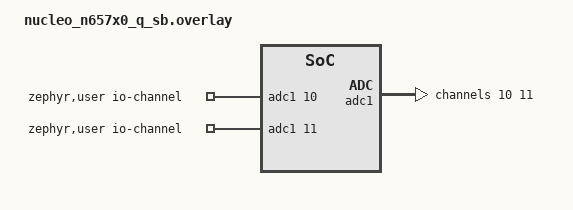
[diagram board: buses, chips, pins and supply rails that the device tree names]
/*
 * SPDX-License-Identifier: Apache-2.0
 *
 * Copyright (c) 2026 Smile
 */

/ {
	zephyr,user {
		/* adjust channel number according to pinmux in board.dts */
		io-channels = <&adc1 10>, <&adc1 11>;
	};
};

&adc1 {
	#address-cells = <1>;
	#size-cells = <0>;

	/*
	 * PA10 (Arduino A2) is shared:
	 * positive input for channel 11 and negative input for channel 10
	 */

	channel@a {
		reg = <10>;
		zephyr,gain = "ADC_GAIN_1";
		zephyr,reference = "ADC_REF_INTERNAL";
		zephyr,acquisition-time = <ADC_ACQ_TIME_DEFAULT>;
		zephyr,resolution = <12>;
		zephyr,differential;
	};

	channel@b {
		reg = <11>;
		zephyr,gain = "ADC_GAIN_1";
		zephyr,reference = "ADC_REF_INTERNAL";
		zephyr,acquisition-time = <ADC_ACQ_TIME_DEFAULT>;
		zephyr,resolution = <12>;
	};
};
